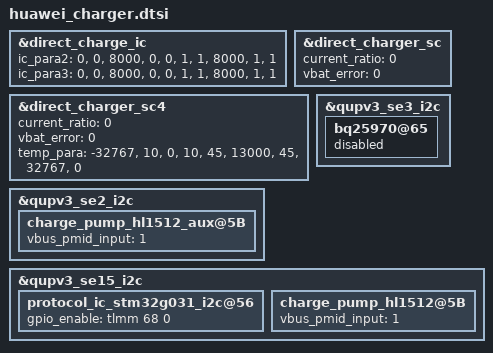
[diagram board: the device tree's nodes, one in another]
&direct_charge_ic {
	ic_para2 =
		"0", "0", "8000", "0", "0",
		"1", "1", "8000", "1", "1";
	ic_para3 =
		"0", "0", "8000", "0", "0",
		"1", "1", "8000", "1", "1";
};

&direct_charger_sc {
	current_ratio = "0";
	vbat_error = "0";
};

&direct_charger_sc4 {
	current_ratio = "0";
	vbat_error = "0";
	temp_para =
		"-32767", "10", "0",
		"10", "45", "13000",
		"45", "32767", "0";
};

&qupv3_se2_i2c {
	charge_pump_hl1512_aux@5B {
		vbus_pmid_input = <1>;
	};
};

&qupv3_se3_i2c {
	bq25970@65 {
		status = "disabled";
	};
};

&qupv3_se15_i2c {
	protocol_ic_stm32g031_i2c@56 {
		gpio_enable = <&tlmm 68 0>;
	};
	charge_pump_hl1512@5B {
		vbus_pmid_input = <1>;
	};
};
